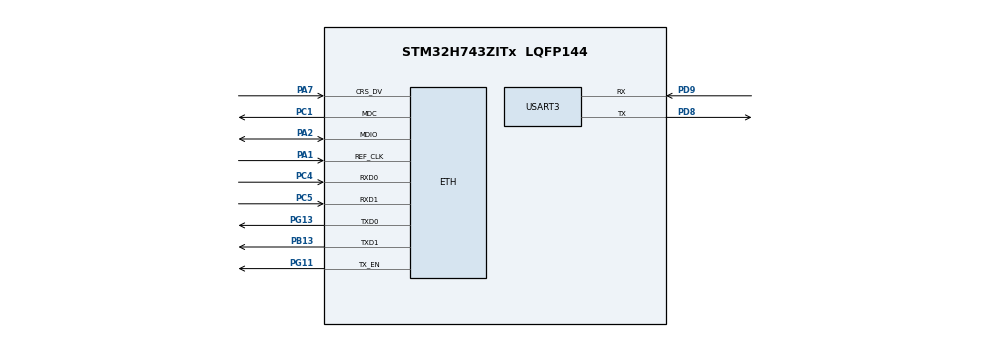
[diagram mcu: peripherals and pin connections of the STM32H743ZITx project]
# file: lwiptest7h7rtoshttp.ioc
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CORTEX_M7.AccessPermission_S-Cortex_Memory_Protection_Unit_Region1_Settings_S=MPU_REGION_FULL_ACCESS
CORTEX_M7.AccessPermission_Spec=MPU_REGION_FULL_ACCESS
CORTEX_M7.BaseAddress_S-Cortex_Memory_Protection_Unit_Region1_Settings_S=0x30000000
CORTEX_M7.BaseAddress_Spec=0x30000000
CORTEX_M7.CPU_DCache=Enabled
CORTEX_M7.CPU_ICache=Enabled
CORTEX_M7.DisableExec_S-Cortex_Memory_Protection_Unit_Region1_Settings_S=MPU_INSTRUCTION_ACCESS_DISABLE
CORTEX_M7.Enable_S-Cortex_Memory_Protection_Unit_Region1_Settings_S=MPU_REGION_ENABLE
CORTEX_M7.IsBufferable_S-Cortex_Memory_Protection_Unit_Region1_Settings_S=MPU_ACCESS_BUFFERABLE
CORTEX_M7.IsShareable_S-Cortex_Memory_Protection_Unit_Region1_Settings_S=MPU_ACCESS_SHAREABLE
CORTEX_M7.IsShareable_Spec=MPU_ACCESS_NOT_SHAREABLE
CORTEX_M7.MPU_Control=MPU_PRIVILEGED_DEFAULT
CORTEX_M7.Size_S-Cortex_Memory_Protection_Unit_Region1_Settings_S=MPU_REGION_SIZE_256B
CORTEX_M7.Size_Spec=MPU_REGION_SIZE_32KB
CORTEX_M7.SubRegionDisable_Spec=0x0
CORTEX_M7.TypeExtField_Spec=MPU_TEX_LEVEL1
CORTEX_M7.default_mode_Activation=1
ETH.MediaInterface=HAL_ETH_RMII_MODE
ETH.RxBufferAddress=0x30000200
ETH.TxDescAddress=0x30000060
FREERTOS.Tasks01=defaultTask,0,256,StartDefaultTask,Default,NULL,Dynamic,NULL,NULL
FREERTOS.configUSE_NEWLIB_REENTRANT=1
LWIP.BSP.number=1
LWIP.GATEWAY_ADDRESS=192.168.001.001
LWIP.IP_ADDRESS=192.168.001.144
LWIP.LWIP_DHCP=0
LWIP.LWIP_DNS=0
LWIP.LWIP_HTTPD=1
LWIP.LWIP_TCP_SACK_OUT=0
LWIP.MEM_SIZE=16360
LWIP.NETMASK_ADDRESS=255.255.255.255
LWIP.Version=v2.1.2_Cube
LWIP0.BSP.STBoard=false
LWIP0.BSP.api=BSP_COMPONENT_DRIVER
LWIP0.BSP.component=LAN8742
LWIP0.BSP.instance=LAN8742
LWIP0.BSP.name=Driver_PHY
LWIP0.BSP.semaphore=S_LAN8742
LWIP0.BSP.solution=LAN8742
Mcu.Family=STM32H7
Mcu.Name=STM32H743ZITx
Mcu.Package=LQFP144
NUCLEO-H743ZI2.BUTTON=1
NUCLEO-H743ZI2.LD1=true
NUCLEO-H743ZI2.LD2=true
NUCLEO-H743ZI2.LD3=true
NUCLEO-H743ZI2.VCP=false
NVIC.ETH_IRQn=true\:5\:0\:false\:false\:true\:true\:true\:true\:true
NVIC.EXTI15_10_IRQn=true\:5\:0\:false\:false\:true\:true\:false\:true\:true
NVIC.PriorityGroup=NVIC_PRIORITYGROUP_4
NVIC.TIM6_DAC_IRQn=true\:15\:0\:false\:false\:true\:false\:false\:true\:true
NVIC.TimeBase=TIM6_DAC_IRQn
NVIC.TimeBaseIP=TIM6
NVIC.USART3_IRQn=true\:5\:0\:false\:false\:true\:true\:true\:true\:true
PA1.Mode=RMII
PA1.Signal=ETH_REF_CLK
PA13\ (JTMS/SWDIO).GPIO_Label=JTMS
PA13\ (JTMS/SWDIO).Signal=DEBUG_JTMS-SWDIO
PA14\ (JTCK/SWCLK).GPIO_Label=JTCK
PA14\ (JTCK/SWCLK).Signal=DEBUG_JTCK-SWCLK
PA2.Mode=RMII
PA2.Signal=ETH_MDIO
PA7.Mode=RMII
PA7.Signal=ETH_CRS_DV
PB13.Mode=RMII
PB13.Signal=ETH_TXD1
PC1.Mode=RMII
PC1.Signal=ETH_MDC
PC14-OSC32_IN\ (OSC32_IN).Signal=RCC_OSC32_IN
PC15-OSC32_OUT\ (OSC32_OUT).Signal=RCC_OSC32_OUT
PC4.Mode=RMII
PC4.Signal=ETH_RXD0
PC5.Mode=RMII
PC5.Signal=ETH_RXD1
PD8.Mode=Asynchronous
PD8.Signal=USART3_TX
PD9.Mode=Asynchronous
PD9.Signal=USART3_RX
PG11.Mode=RMII
PG11.Signal=ETH_TX_EN
PG13.Mode=RMII
PG13.Signal=ETH_TXD0
PH0-OSC_IN\ (PH0).Signal=RCC_OSC_IN
PH1-OSC_OUT\ (PH1).Signal=RCC_OSC_OUT
ProjectManager.HeapSize=0x200
ProjectManager.StackSize=0x400
ProjectManager.TargetToolchain=STM32CubeIDE
RCC.ADCFreq_Value=129000000
RCC.APB1Freq_Value=100000000
RCC.APB2Freq_Value=100000000
RCC.APB3Freq_Value=100000000
RCC.APB4Freq_Value=100000000
RCC.CortexFreq_Value=400000000
RCC.D1PPRE=RCC_APB3_DIV2
RCC.D2PPRE1=RCC_APB1_DIV2
RCC.D2PPRE2=RCC_APB2_DIV2
RCC.D3PPRE=RCC_APB4_DIV2
RCC.DIVM1=4
RCC.DIVN1=50
RCC.HCLKFreq_Value=200000000
RCC.HPRE=RCC_HCLK_DIV2
RCC.PLL2FRACN=0
RCC.PLL3FRACN=0
RCC.PLLFRACN=0
RCC.SYSCLKFreq_VALUE=400000000
RCC.SYSCLKSource=RCC_SYSCLKSOURCE_PLLCLK
RCC.USBFreq_Value=400000000
USART3.VirtualMode-Asynchronous=VM_ASYNC
VP_FREERTOS_VS_CMSIS_V1.Mode=CMSIS_V1
VP_LWIP_VS_Enabled.Mode=Enabled
VP_MEMORYMAP_VS_MEMORYMAP.Mode=CurAppReg
VP_NUCLEO-H743ZI2_VS_BSP_COMMON.Mode=COMMON
VP_SYS_VS_tim6.Mode=TIM6
board=NUCLEO-H743ZI2

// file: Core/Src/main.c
/* USER CODE BEGIN Header */
/**
  ******************************************************************************
  * @file           : main.c
  * @brief          : Main program body
  ******************************************************************************
  * @attention
  *
  * Copyright (c) 2025 STMicroelectronics.
  * All rights reserved.
  *
  * This software is licensed under terms that can be found in the LICENSE file
  * in the root directory of this software component.
  * If no LICENSE file comes with this software, it is provided AS-IS.
  *
  ******************************************************************************
  */
/* USER CODE END Header */
#include "main.h"
#include "cmsis_os.h"
#include "lwip.h"

/* USER CODE BEGIN Includes */
#include "lwip/apps/httpd.h"
/* USER CODE END Includes */

UART_HandleTypeDef huart3;

osThreadId defaultTaskHandle;

void SystemClock_Config(void);
static void MPU_Config(void);
static void MX_GPIO_Init(void);
static void MX_USART3_UART_Init(void);
void StartDefaultTask(void const * argument);

int main(void)
{

  /* MPU Configuration--------------------------------------------------------*/
  MPU_Config();

  /* Enable the CPU Cache */

  /* Enable I-Cache---------------------------------------------------------*/
  SCB_EnableICache();

  /* Enable D-Cache---------------------------------------------------------*/
  SCB_EnableDCache();

  /* MCU Configuration--------------------------------------------------------*/

  /* Reset of all peripherals, Initializes the Flash interface and the Systick. */
  HAL_Init();

  /* Configure the system clock */
  SystemClock_Config();

  /* Initialize all configured peripherals */
  MX_GPIO_Init();
  MX_USART3_UART_Init();
  /* USER CODE BEGIN 2 */
  startUART();
  /* USER CODE END 2 */

  /* Create the thread(s) */
  /* definition and creation of defaultTask */
  osThreadDef(defaultTask, StartDefaultTask, osPriorityNormal, 0, 256);
  defaultTaskHandle = osThreadCreate(osThread(defaultTask), NULL);

  /* Initialize leds */
  BSP_LED_Init(LED_GREEN);
  BSP_LED_Init(LED_YELLOW);
  BSP_LED_Init(LED_RED);

  /* Initialize USER push-button, will be used to trigger an interrupt each time it's pressed.*/
  BSP_PB_Init(BUTTON_USER, BUTTON_MODE_EXTI);

  /* Start scheduler */
  osKernelStart();

  /* We should never get here as control is now taken by the scheduler */

  /* Infinite loop */
  while (1)
  {

  }
}

void SystemClock_Config(void)
{
  RCC_OscInitTypeDef RCC_OscInitStruct = {0};
  RCC_ClkInitTypeDef RCC_ClkInitStruct = {0};

  /** Supply configuration update enable
  */
  HAL_PWREx_ConfigSupply(PWR_LDO_SUPPLY);

  /** Configure the main internal regulator output voltage
  */
  __HAL_PWR_VOLTAGESCALING_CONFIG(PWR_REGULATOR_VOLTAGE_SCALE1);

  while(!__HAL_PWR_GET_FLAG(PWR_FLAG_VOSRDY)) {}

  /** Initializes the RCC Oscillators according to the specified parameters
  * in the RCC_OscInitTypeDef structure.
  */
  RCC_OscInitStruct.OscillatorType = RCC_OSCILLATORTYPE_HSI;
  RCC_OscInitStruct.HSIState = RCC_HSI_DIV1;
  RCC_OscInitStruct.HSICalibrationValue = RCC_HSICALIBRATION_DEFAULT;
  RCC_OscInitStruct.PLL.PLLState = RCC_PLL_ON;
  RCC_OscInitStruct.PLL.PLLSource = RCC_PLLSOURCE_HSI;
  RCC_OscInitStruct.PLL.PLLM = 4;
  RCC_OscInitStruct.PLL.PLLN = 50;
  RCC_OscInitStruct.PLL.PLLP = 2;
  RCC_OscInitStruct.PLL.PLLQ = 2;
  RCC_OscInitStruct.PLL.PLLR = 2;
  RCC_OscInitStruct.PLL.PLLRGE = RCC_PLL1VCIRANGE_3;
  RCC_OscInitStruct.PLL.PLLVCOSEL = RCC_PLL1VCOWIDE;
  RCC_OscInitStruct.PLL.PLLFRACN = 0;
  if (HAL_RCC_OscConfig(&RCC_OscInitStruct) != HAL_OK)
  {
    Error_Handler();
  }

  /** Initializes the CPU, AHB and APB buses clocks
  */
  RCC_ClkInitStruct.ClockType = RCC_CLOCKTYPE_HCLK|RCC_CLOCKTYPE_SYSCLK
                              |RCC_CLOCKTYPE_PCLK1|RCC_CLOCKTYPE_PCLK2
                              |RCC_CLOCKTYPE_D3PCLK1|RCC_CLOCKTYPE_D1PCLK1;
  RCC_ClkInitStruct.SYSCLKSource = RCC_SYSCLKSOURCE_PLLCLK;
  RCC_ClkInitStruct.SYSCLKDivider = RCC_SYSCLK_DIV1;
  RCC_ClkInitStruct.AHBCLKDivider = RCC_HCLK_DIV2;
  RCC_ClkInitStruct.APB3CLKDivider = RCC_APB3_DIV2;
  RCC_ClkInitStruct.APB1CLKDivider = RCC_APB1_DIV2;
  RCC_ClkInitStruct.APB2CLKDivider = RCC_APB2_DIV2;
  RCC_ClkInitStruct.APB4CLKDivider = RCC_APB4_DIV2;

  if (HAL_RCC_ClockConfig(&RCC_ClkInitStruct, FLASH_LATENCY_2) != HAL_OK)
  {
    Error_Handler();
  }
}

static void MX_USART3_UART_Init(void)
{

  huart3.Instance = USART3;
  huart3.Init.BaudRate = 115200;
  huart3.Init.WordLength = UART_WORDLENGTH_8B;
  huart3.Init.StopBits = UART_STOPBITS_1;
  huart3.Init.Parity = UART_PARITY_NONE;
  huart3.Init.Mode = UART_MODE_TX_RX;
  huart3.Init.HwFlowCtl = UART_HWCONTROL_NONE;
  huart3.Init.OverSampling = UART_OVERSAMPLING_16;
  huart3.Init.OneBitSampling = UART_ONE_BIT_SAMPLE_DISABLE;
  huart3.Init.ClockPrescaler = UART_PRESCALER_DIV1;
  huart3.AdvancedInit.AdvFeatureInit = UART_ADVFEATURE_NO_INIT;
  if (HAL_UART_Init(&huart3) != HAL_OK)
  {
    Error_Handler();
  }
  if (HAL_UARTEx_SetTxFifoThreshold(&huart3, UART_TXFIFO_THRESHOLD_1_8) != HAL_OK)
  {
    Error_Handler();
  }
  if (HAL_UARTEx_SetRxFifoThreshold(&huart3, UART_RXFIFO_THRESHOLD_1_8) != HAL_OK)
  {
    Error_Handler();
  }
  if (HAL_UARTEx_DisableFifoMode(&huart3) != HAL_OK)
  {
    Error_Handler();
  }

}

static void MX_GPIO_Init(void)
{

  /* GPIO Ports Clock Enable */
  __HAL_RCC_GPIOC_CLK_ENABLE();
  __HAL_RCC_GPIOH_CLK_ENABLE();
  __HAL_RCC_GPIOA_CLK_ENABLE();
  __HAL_RCC_GPIOB_CLK_ENABLE();
  __HAL_RCC_GPIOD_CLK_ENABLE();
  __HAL_RCC_GPIOG_CLK_ENABLE();

}

void StartDefaultTask(void const * argument)
{
  /* init code for LWIP */
  MX_LWIP_Init();
  udpServer_init();
  tcp_server_init();
  httpd_init();
  for(;;)
  {
    osDelay(1);
  }
}

 /* MPU Configuration */

void MPU_Config(void)
{
  MPU_Region_InitTypeDef MPU_InitStruct = {0};

  /* Disables the MPU */
  HAL_MPU_Disable();

  /** Initializes and configures the Region and the memory to be protected
  */
  MPU_InitStruct.Enable = MPU_REGION_ENABLE;
  MPU_InitStruct.Number = MPU_REGION_NUMBER0;
  MPU_InitStruct.BaseAddress = 0x30000000;
  MPU_InitStruct.Size = MPU_REGION_SIZE_32KB;
  MPU_InitStruct.SubRegionDisable = 0x0;
  MPU_InitStruct.TypeExtField = MPU_TEX_LEVEL1;
  MPU_InitStruct.AccessPermission = MPU_REGION_FULL_ACCESS;
  MPU_InitStruct.DisableExec = MPU_INSTRUCTION_ACCESS_DISABLE;
  MPU_InitStruct.IsShareable = MPU_ACCESS_NOT_SHAREABLE;
  MPU_InitStruct.IsCacheable = MPU_ACCESS_NOT_CACHEABLE;
  MPU_InitStruct.IsBufferable = MPU_ACCESS_NOT_BUFFERABLE;

  HAL_MPU_ConfigRegion(&MPU_InitStruct);

  /** Initializes and configures the Region and the memory to be protected
  */
  MPU_InitStruct.Number = MPU_REGION_NUMBER1;
  MPU_InitStruct.Size = MPU_REGION_SIZE_256B;
  MPU_InitStruct.TypeExtField = MPU_TEX_LEVEL0;
  MPU_InitStruct.IsShareable = MPU_ACCESS_SHAREABLE;
  MPU_InitStruct.IsBufferable = MPU_ACCESS_BUFFERABLE;

  HAL_MPU_ConfigRegion(&MPU_InitStruct);
  /* Enables the MPU */
  HAL_MPU_Enable(MPU_PRIVILEGED_DEFAULT);

}

void HAL_TIM_PeriodElapsedCallback(TIM_HandleTypeDef *htim)
{
  if (htim->Instance == TIM6) {
    HAL_IncTick();
  }
}

void Error_Handler(void)
{
  __disable_irq();
  while (1)
  {
  }
}
